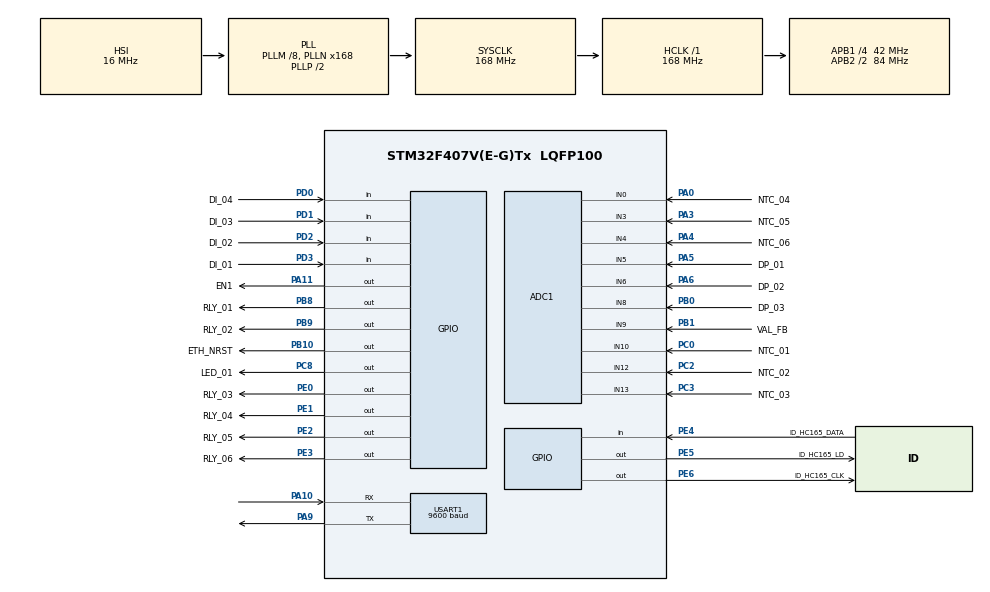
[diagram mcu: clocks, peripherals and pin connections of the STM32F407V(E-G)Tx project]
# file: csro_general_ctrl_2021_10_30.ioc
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ADC1.Channel-13\#ChannelRegularConversion=ADC_CHANNEL_0
ADC1.Channel-14\#ChannelRegularConversion=ADC_CHANNEL_3
ADC1.ContinuousConvMode=ENABLE
ADC1.DMAContinuousRequests=ENABLE
ADC1.NbrOfConversion=2
ADC1.NbrOfConversionFlag=1
ADC1.Rank-13\#ChannelRegularConversion=1
ADC1.Rank-14\#ChannelRegularConversion=2
ADC1.SamplingTime-13\#ChannelRegularConversion=ADC_SAMPLETIME_144CYCLES
ADC1.SamplingTime-14\#ChannelRegularConversion=ADC_SAMPLETIME_144CYCLES
ADC1.ScanConvMode=ENABLE
ADC1.master=1
Dma.ADC1.2.Direction=DMA_PERIPH_TO_MEMORY
Dma.ADC1.2.FIFOMode=DMA_FIFOMODE_DISABLE
Dma.ADC1.2.Instance=DMA2_Stream0
Dma.ADC1.2.MemDataAlignment=DMA_MDATAALIGN_WORD
Dma.ADC1.2.MemInc=DMA_MINC_ENABLE
Dma.ADC1.2.Mode=DMA_CIRCULAR
Dma.ADC1.2.PeriphDataAlignment=DMA_PDATAALIGN_WORD
Dma.ADC1.2.PeriphInc=DMA_PINC_DISABLE
Dma.ADC1.2.Priority=DMA_PRIORITY_LOW
Dma.MEMTOMEM.3.Direction=DMA_MEMORY_TO_MEMORY
Dma.MEMTOMEM.3.FIFOMode=DMA_FIFOMODE_ENABLE
Dma.MEMTOMEM.3.FIFOThreshold=DMA_FIFO_THRESHOLD_FULL
Dma.MEMTOMEM.3.Instance=DMA2_Stream1
Dma.MEMTOMEM.3.MemBurst=DMA_MBURST_SINGLE
Dma.MEMTOMEM.3.MemDataAlignment=DMA_MDATAALIGN_BYTE
Dma.MEMTOMEM.3.MemInc=DMA_MINC_ENABLE
Dma.MEMTOMEM.3.Mode=DMA_NORMAL
Dma.MEMTOMEM.3.PeriphBurst=DMA_PBURST_SINGLE
Dma.MEMTOMEM.3.PeriphDataAlignment=DMA_PDATAALIGN_BYTE
Dma.MEMTOMEM.3.PeriphInc=DMA_PINC_ENABLE
Dma.MEMTOMEM.3.Priority=DMA_PRIORITY_LOW
Dma.Request0=USART1_RX
Dma.Request1=USART1_TX
Dma.Request2=ADC1
Dma.Request3=MEMTOMEM
Dma.USART1_RX.0.Direction=DMA_PERIPH_TO_MEMORY
Dma.USART1_RX.0.FIFOMode=DMA_FIFOMODE_DISABLE
Dma.USART1_RX.0.Instance=DMA2_Stream2
Dma.USART1_RX.0.MemDataAlignment=DMA_MDATAALIGN_BYTE
Dma.USART1_RX.0.MemInc=DMA_MINC_ENABLE
Dma.USART1_RX.0.Mode=DMA_CIRCULAR
Dma.USART1_RX.0.PeriphDataAlignment=DMA_PDATAALIGN_BYTE
Dma.USART1_RX.0.PeriphInc=DMA_PINC_DISABLE
Dma.USART1_RX.0.Priority=DMA_PRIORITY_LOW
Dma.USART1_TX.1.Direction=DMA_MEMORY_TO_PERIPH
Dma.USART1_TX.1.FIFOMode=DMA_FIFOMODE_DISABLE
Dma.USART1_TX.1.Instance=DMA2_Stream7
Dma.USART1_TX.1.MemDataAlignment=DMA_MDATAALIGN_BYTE
Dma.USART1_TX.1.MemInc=DMA_MINC_ENABLE
Dma.USART1_TX.1.Mode=DMA_NORMAL
Dma.USART1_TX.1.PeriphDataAlignment=DMA_PDATAALIGN_BYTE
Dma.USART1_TX.1.PeriphInc=DMA_PINC_DISABLE
Dma.USART1_TX.1.Priority=DMA_PRIORITY_LOW
FREERTOS.Tasks01=myTask01,47,128,StartTask01,Default,NULL,Dynamic,NULL,NULL;myTask02,45,128,StartTask02,Default,NULL,Dynamic,NULL,NULL;myTask03,43,128,StartTask03,Default,NULL,Dynamic,NULL,NULL;myTask04,41,128,StartTask04,Default,NULL,Dynamic,NULL,NULL;myTask05,39,128,StartTask05,Default,NULL,Dynamic,NULL,NULL;myTask06,37,128,StartTask06,Default,NULL,Dynamic,NULL,NULL;myTask07,35,128,StartTask07,Default,NULL,Dynamic,NULL,NULL;myTask08,33,128,StartTask08,Default,NULL,Dynamic,NULL,NULL
FREERTOS.configUSE_NEWLIB_REENTRANT=1
Mcu.Family=STM32F4
Mcu.Name=STM32F407V(E-G)Tx
Mcu.Package=LQFP100
NVIC.DMA2_Stream0_IRQn=true\:5\:0\:false\:false\:true\:true\:false\:true
NVIC.DMA2_Stream2_IRQn=true\:5\:0\:false\:false\:true\:true\:false\:true
NVIC.DMA2_Stream7_IRQn=true\:5\:0\:false\:false\:true\:true\:false\:true
NVIC.PriorityGroup=NVIC_PRIORITYGROUP_4
NVIC.TIM8_TRG_COM_TIM14_IRQn=true\:15\:0\:false\:false\:true\:false\:false\:true
NVIC.TimeBase=TIM8_TRG_COM_TIM14_IRQn
NVIC.TimeBaseIP=TIM14
NVIC.USART1_IRQn=true\:5\:0\:false\:false\:true\:true\:true\:true
PA0-WKUP.GPIO_Label=NTC_04
PA0-WKUP.Signal=ADCx_IN0
PA10.Mode=Asynchronous
PA10.Signal=USART1_RX
PA11.GPIO_Label=EN1
PA11.Signal=GPIO_Output
PA13.GPIO_Label=SWDIO
PA13.Mode=Serial_Wire
PA13.Signal=SYS_JTMS-SWDIO
PA14.GPIO_Label=SWCLK
PA14.Mode=Serial_Wire
PA14.Signal=SYS_JTCK-SWCLK
PA3.GPIO_Label=NTC_05
PA3.Signal=ADCx_IN3
PA4.GPIO_Label=NTC_06
PA4.Signal=ADCx_IN4
PA5.GPIO_Label=DP_01
PA5.Signal=ADCx_IN5
PA6.GPIO_Label=DP_02
PA6.Signal=ADCx_IN6
PA9.Mode=Asynchronous
PA9.Signal=USART1_TX
PB0.GPIO_Label=DP_03
PB0.Signal=ADCx_IN8
PB1.GPIO_Label=VAL_FB
PB1.Signal=ADCx_IN9
PB10.GPIO_Label=ETH_NRST
PB10.Signal=GPIO_Output
PB8.GPIO_Label=RLY_01
PB8.Signal=GPIO_Output
PB9.GPIO_Label=RLY_02
PB9.Signal=GPIO_Output
PC0.GPIO_Label=NTC_01
PC0.Signal=ADCx_IN10
PC2.GPIO_Label=NTC_02
PC2.Signal=ADCx_IN12
PC3.GPIO_Label=NTC_03
PC3.Signal=ADCx_IN13
PC8.GPIO_Label=LED_01
PC8.Signal=GPIO_Output
PD0.GPIO_Label=DI_04
PD0.Signal=GPIO_Input
PD1.GPIO_Label=DI_03
PD1.Signal=GPIO_Input
PD2.GPIO_Label=DI_02
PD2.Signal=GPIO_Input
PD3.GPIO_Label=DI_01
PD3.Signal=GPIO_Input
PE0.GPIO_Label=RLY_03
PE0.Signal=GPIO_Output
PE1.GPIO_Label=RLY_04
PE1.Signal=GPIO_Output
PE2.GPIO_Label=RLY_05
PE2.Signal=GPIO_Output
PE3.GPIO_Label=RLY_06
PE3.Signal=GPIO_Output
PE4.GPIO_Label=ID_HC165_DATA
PE4.Signal=GPIO_Input
PE5.GPIO_Label=ID_HC165_LD
PE5.Signal=GPIO_Output
PE6.GPIO_Label=ID_HC165_CLK
PE6.Signal=GPIO_Output
ProjectManager.HeapSize=0x800
ProjectManager.StackSize=0x800
ProjectManager.TargetToolchain=STM32CubeIDE
RCC.48MHZClocksFreq_Value=84000000
RCC.AHBFreq_Value=168000000
RCC.APB1CLKDivider=RCC_HCLK_DIV4
RCC.APB1Freq_Value=42000000
RCC.APB1TimFreq_Value=84000000
RCC.APB2CLKDivider=RCC_HCLK_DIV2
RCC.APB2Freq_Value=84000000
RCC.APB2TimFreq_Value=168000000
RCC.CortexFreq_Value=168000000
RCC.HCLKFreq_Value=168000000
RCC.HSE_VALUE=25000000
RCC.HSI_VALUE=16000000
RCC.LSE_VALUE=32768
RCC.PLLM=8
RCC.PLLN=168
RCC.SYSCLKFreq_VALUE=168000000
RCC.SYSCLKSource=RCC_SYSCLKSOURCE_PLLCLK
RCC.VCOOutputFreq_Value=336000000
SH.ADCx_IN0.0=ADC1_IN0,IN0
SH.ADCx_IN10.0=ADC1_IN10,IN10
SH.ADCx_IN12.0=ADC1_IN12,IN12
SH.ADCx_IN13.0=ADC1_IN13,IN13
SH.ADCx_IN3.0=ADC1_IN3,IN3
SH.ADCx_IN4.0=ADC1_IN4,IN4
SH.ADCx_IN5.0=ADC1_IN5,IN5
SH.ADCx_IN6.0=ADC1_IN6,IN6
SH.ADCx_IN8.0=ADC1_IN8,IN8
SH.ADCx_IN9.0=ADC1_IN9,IN9
USART1.BaudRate=9600
USART1.VirtualMode=VM_ASYNC
VP_ADC1_TempSens_Input.Mode=IN-TempSens
VP_ADC1_Vbat_Input.Mode=IN-Vbat
VP_ADC1_Vref_Input.Mode=IN-Vrefint
VP_FREERTOS_VS_CMSIS_V2.Mode=CMSIS_V2
VP_SYS_VS_tim14.Mode=TIM14
board=custom

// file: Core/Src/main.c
/* USER CODE BEGIN Header */
/**
  ******************************************************************************
  * @file           : main.c
  * @brief          : Main program body
  ******************************************************************************
  * @attention
  *
  * <h2><center>&copy; Copyright (c) 2021 STMicroelectronics.
  * All rights reserved.</center></h2>
  *
  * This software component is licensed by ST under Ultimate Liberty license
  * SLA0044, the "License"; You may not use this file except in compliance with
  * the License. You may obtain a copy of the License at:
  *                             www.st.com/SLA0044
  *
  ******************************************************************************
  */
/* USER CODE END Header */
#include "main.h"
#include "cmsis_os.h"
#include "adc.h"
#include "dma.h"
#include "usart.h"
#include "gpio.h"

void SystemClock_Config(void);
void MX_FREERTOS_Init(void);

int main(void)
{

  /* MCU Configuration--------------------------------------------------------*/

  /* Reset of all peripherals, Initializes the Flash interface and the Systick. */
  HAL_Init();

  /* Configure the system clock */
  SystemClock_Config();

  /* Initialize all configured peripherals */
  MX_GPIO_Init();
  MX_DMA_Init();
  MX_USART1_UART_Init();
  MX_ADC1_Init();

  /* Init scheduler */
  osKernelInitialize();  /* Call init function for freertos objects (in freertos.c) */
  MX_FREERTOS_Init();
  /* Start scheduler */
  osKernelStart();

  /* We should never get here as control is now taken by the scheduler */
  /* Infinite loop */
  while (1)
  {

  }
}

void SystemClock_Config(void)
{
  RCC_OscInitTypeDef RCC_OscInitStruct = {0};
  RCC_ClkInitTypeDef RCC_ClkInitStruct = {0};

  /** Configure the main internal regulator output voltage
  */
  __HAL_RCC_PWR_CLK_ENABLE();
  __HAL_PWR_VOLTAGESCALING_CONFIG(PWR_REGULATOR_VOLTAGE_SCALE1);
  /** Initializes the RCC Oscillators according to the specified parameters
  * in the RCC_OscInitTypeDef structure.
  */
  RCC_OscInitStruct.OscillatorType = RCC_OSCILLATORTYPE_HSI;
  RCC_OscInitStruct.HSIState = RCC_HSI_ON;
  RCC_OscInitStruct.HSICalibrationValue = RCC_HSICALIBRATION_DEFAULT;
  RCC_OscInitStruct.PLL.PLLState = RCC_PLL_ON;
  RCC_OscInitStruct.PLL.PLLSource = RCC_PLLSOURCE_HSI;
  RCC_OscInitStruct.PLL.PLLM = 8;
  RCC_OscInitStruct.PLL.PLLN = 168;
  RCC_OscInitStruct.PLL.PLLP = RCC_PLLP_DIV2;
  RCC_OscInitStruct.PLL.PLLQ = 4;
  if (HAL_RCC_OscConfig(&RCC_OscInitStruct) != HAL_OK)
  {
    Error_Handler();
  }
  /** Initializes the CPU, AHB and APB buses clocks
  */
  RCC_ClkInitStruct.ClockType = RCC_CLOCKTYPE_HCLK|RCC_CLOCKTYPE_SYSCLK
                              |RCC_CLOCKTYPE_PCLK1|RCC_CLOCKTYPE_PCLK2;
  RCC_ClkInitStruct.SYSCLKSource = RCC_SYSCLKSOURCE_PLLCLK;
  RCC_ClkInitStruct.AHBCLKDivider = RCC_SYSCLK_DIV1;
  RCC_ClkInitStruct.APB1CLKDivider = RCC_HCLK_DIV4;
  RCC_ClkInitStruct.APB2CLKDivider = RCC_HCLK_DIV2;

  if (HAL_RCC_ClockConfig(&RCC_ClkInitStruct, FLASH_LATENCY_5) != HAL_OK)
  {
    Error_Handler();
  }
}

void HAL_TIM_PeriodElapsedCallback(TIM_HandleTypeDef *htim)
{
  if (htim->Instance == TIM14) {
    HAL_IncTick();
  }
}

void Error_Handler(void)
{
  __disable_irq();
  while (1)
  {
  }
}

/************************ (C) COPYRIGHT STMicroelectronics *****END OF FILE****/

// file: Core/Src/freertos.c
/* USER CODE BEGIN Header */
/**
 ******************************************************************************
 * File Name          : freertos.c
 * Description        : Code for freertos applications
 ******************************************************************************
 * @attention
 *
 * <h2><center>&copy; Copyright (c) 2021 STMicroelectronics.
 * All rights reserved.</center></h2>
 *
 * This software component is licensed by ST under Ultimate Liberty license
 * SLA0044, the "License"; You may not use this file except in compliance with
 * the License. You may obtain a copy of the License at:
 *                             www.st.com/SLA0044
 *
 ******************************************************************************
 */
/* USER CODE END Header */

#include "FreeRTOS.h"
#include "task.h"
#include "main.h"
#include "cmsis_os.h"

/* USER CODE BEGIN Includes */
#include "gpio.h"
#include "fnd_input.h"

/* USER CODE END Includes */

/* Definitions for myTask01 */
osThreadId_t myTask01Handle;
const osThreadAttr_t myTask01_attributes = {
  .name = "myTask01",
  .stack_size = 128 * 4,
  .priority = (osPriority_t) osPriorityHigh7,
};
/* Definitions for myTask02 */
osThreadId_t myTask02Handle;
const osThreadAttr_t myTask02_attributes = {
  .name = "myTask02",
  .stack_size = 128 * 4,
  .priority = (osPriority_t) osPriorityHigh5,
};
/* Definitions for myTask03 */
osThreadId_t myTask03Handle;
const osThreadAttr_t myTask03_attributes = {
  .name = "myTask03",
  .stack_size = 128 * 4,
  .priority = (osPriority_t) osPriorityHigh3,
};
/* Definitions for myTask04 */
osThreadId_t myTask04Handle;
const osThreadAttr_t myTask04_attributes = {
  .name = "myTask04",
  .stack_size = 128 * 4,
  .priority = (osPriority_t) osPriorityHigh1,
};
/* Definitions for myTask05 */
osThreadId_t myTask05Handle;
const osThreadAttr_t myTask05_attributes = {
  .name = "myTask05",
  .stack_size = 128 * 4,
  .priority = (osPriority_t) osPriorityAboveNormal7,
};
/* Definitions for myTask06 */
osThreadId_t myTask06Handle;
const osThreadAttr_t myTask06_attributes = {
  .name = "myTask06",
  .stack_size = 128 * 4,
  .priority = (osPriority_t) osPriorityAboveNormal5,
};
/* Definitions for myTask07 */
osThreadId_t myTask07Handle;
const osThreadAttr_t myTask07_attributes = {
  .name = "myTask07",
  .stack_size = 128 * 4,
  .priority = (osPriority_t) osPriorityAboveNormal3,
};
/* Definitions for myTask08 */
osThreadId_t myTask08Handle;
const osThreadAttr_t myTask08_attributes = {
  .name = "myTask08",
  .stack_size = 128 * 4,
  .priority = (osPriority_t) osPriorityAboveNormal1,
};

void StartTask01(void *argument);
void StartTask02(void *argument);
void StartTask03(void *argument);
void StartTask04(void *argument);
void StartTask05(void *argument);
void StartTask06(void *argument);
void StartTask07(void *argument);
void StartTask08(void *argument);

void MX_FREERTOS_Init(void); /* (MISRA C 2004 rule 8.1) */

void MX_FREERTOS_Init(void) {

  /* Create the thread(s) */
  /* creation of myTask01 */
  myTask01Handle = osThreadNew(StartTask01, NULL, &myTask01_attributes);

  /* creation of myTask02 */
  myTask02Handle = osThreadNew(StartTask02, NULL, &myTask02_attributes);

  /* creation of myTask03 */
  myTask03Handle = osThreadNew(StartTask03, NULL, &myTask03_attributes);

  /* creation of myTask04 */
  myTask04Handle = osThreadNew(StartTask04, NULL, &myTask04_attributes);

  /* creation of myTask05 */
  myTask05Handle = osThreadNew(StartTask05, NULL, &myTask05_attributes);

  /* creation of myTask06 */
  myTask06Handle = osThreadNew(StartTask06, NULL, &myTask06_attributes);

  /* creation of myTask07 */
  myTask07Handle = osThreadNew(StartTask07, NULL, &myTask07_attributes);

  /* creation of myTask08 */
  myTask08Handle = osThreadNew(StartTask08, NULL, &myTask08_attributes);

}

void StartTask01(void *argument)
{
  for (;;)
  {
    osDelay(1);
  }
}

void StartTask02(void *argument)
{
  for (;;)
  {
    osDelay(1);
  }
}

void StartTask03(void *argument)
{
  for (;;)
  {
    osDelay(1);
  }
}

void StartTask04(void *argument)
{
  for (;;)
  {
    osDelay(1);
  }
}

void StartTask05(void *argument)
{
  for (;;)
  {
    osDelay(1);
  }
}

void StartTask06(void *argument)
{
  for (;;)
  {
    osDelay(1);
  }
}

void StartTask07(void *argument)
{
  /* USER CODE BEGIN StartTask07 */
  fnd_input_adc_init();
  /* Infinite loop */
  for (;;)
  {
    osDelay(1);
  }
  /* USER CODE END StartTask07 */
}

void StartTask08(void *argument)
{
  /* USER CODE BEGIN StartTask08 */
  HAL_GPIO_WritePin(ETH_NRST_GPIO_Port, ETH_NRST_Pin, GPIO_PIN_SET);
  /* Infinite loop */
  for (;;)
  {
    osDelay(500);
    HAL_GPIO_TogglePin(LED_01_GPIO_Port, LED_01_Pin);
  }
  /* USER CODE END StartTask08 */
}

/************************ (C) COPYRIGHT STMicroelectronics *****END OF FILE****/
